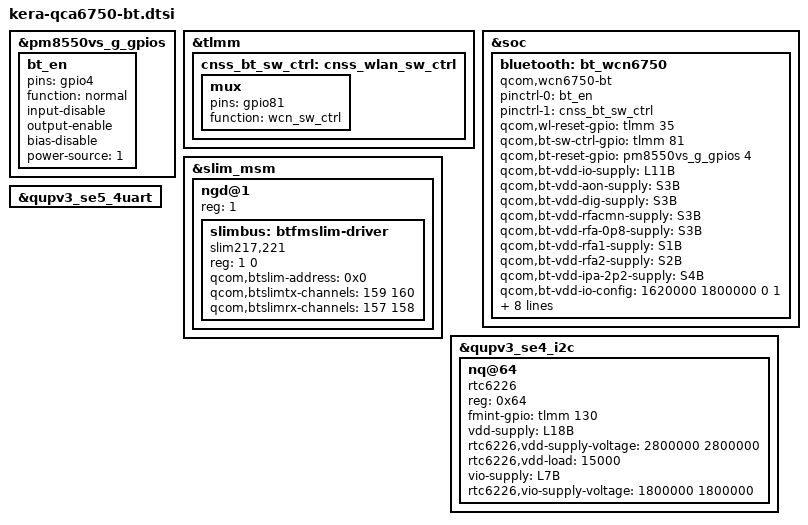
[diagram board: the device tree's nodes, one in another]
// SPDX-License-Identifier: BSD-3-Clause

/*
 * Copyright (c) 2024 Qualcomm Innovation Center, Inc. All rights reserved.
 */

#include <dt-bindings/interrupt-controller/arm-gic.h>
#include <dt-bindings/interconnect/qcom,kera.h>
#include <dt-bindings/clock/qcom,rpmh.h>

&pm8550vs_g_gpios {
	bt_en: bt_en {
		pins = "gpio4";
		function = "normal";
		input-disable;
		output-enable;
		bias-disable;
		power-source = <1>;
	};
};

&tlmm {
	cnss_bt_sw_ctrl: cnss_wlan_sw_ctrl {
		mux {
			pins = "gpio81";
			function = "wcn_sw_ctrl";
		};
	};
};

&soc {
	bluetooth: bt_wcn6750 {
		compatible = "qcom,wcn6750-bt";

		pinctrl-names = "bt_en", "sw_ctrl";
		pinctrl-0 = <&bt_en>;
		pinctrl-1 = <&cnss_bt_sw_ctrl>;

		qcom,wl-reset-gpio   = <&tlmm 35 0>; /* WCN_WLAN_EN */
		qcom,bt-sw-ctrl-gpio = <&tlmm 81 0>; /* WCN_SW_CTRL */
		qcom,bt-reset-gpio   = <&pm8550vs_g_gpios 4 0>; /* WCN_BT_EN */

		qcom,bt-vdd-io-supply = <&L11B>;  /* IO */
		qcom,bt-vdd-aon-supply = <&S3B>;
		qcom,bt-vdd-dig-supply = <&S3B>; /* BT_CX_MX */
		qcom,bt-vdd-rfacmn-supply = <&S3B>;
		qcom,bt-vdd-rfa-0p8-supply = <&S3B>;
		qcom,bt-vdd-rfa1-supply = <&S1B>; /*RFA 1p7*/
		qcom,bt-vdd-rfa2-supply = <&S2B>; /*RFA 1p2*/
		qcom,bt-vdd-ipa-2p2-supply = <&S4B>; /*IPA 2p2*/

		/* max voltage are set to regulator max voltage supported */
		qcom,bt-vdd-io-config = <1620000 1800000 0 1>;
		qcom,bt-vdd-aon-config = <920000 2736000 0 1>;
		qcom,bt-vdd-dig-config = <920000 2736000 0 1>;
		qcom,bt-vdd-rfacmn-config  = <920000 2736000 0 1>;
		qcom,bt-vdd-rfa-0p8-config  = <920000 2736000 0 1>;
		qcom,bt-vdd-rfa1-config = <1856000 2044000 0 1>;
		qcom,bt-vdd-rfa2-config = <1256000 2092000 0 1>;
		qcom,bt-vdd-ipa-2p2-config = <2200000 2700000 0 1>;
	};

};

&slim_msm {
	status =  "ok";
	ngd@1 {
		reg = <1>;
		#address-cells = <1>;
		#size-cells = <1>;
		//slimbus child nodes
		slimbus: btfmslim-driver {
			compatible = "slim217,221";
			reg = <1 0>;
			qcom,btslim-address  = <0x0>;
			qcom,btslimtx-channels = <159 160>;
			qcom,btslimrx-channels = <157 158>;
		};
	};
};

//uart instance
&qupv3_se5_4uart {
	status = "ok";
};

// FM changes
&qupv3_se4_i2c {
	status = "ok";
	nq@64 {
		compatible = "rtc6226";
		reg = <0x64>;
		fmint-gpio = <&tlmm 130 0>;
		vdd-supply = <&L18B>;
		rtc6226,vdd-supply-voltage = <2800000 2800000>;
		rtc6226,vdd-load = <15000>;
		vio-supply = <&L7B>;
		rtc6226,vio-supply-voltage = <1800000 1800000>;
	};
};
